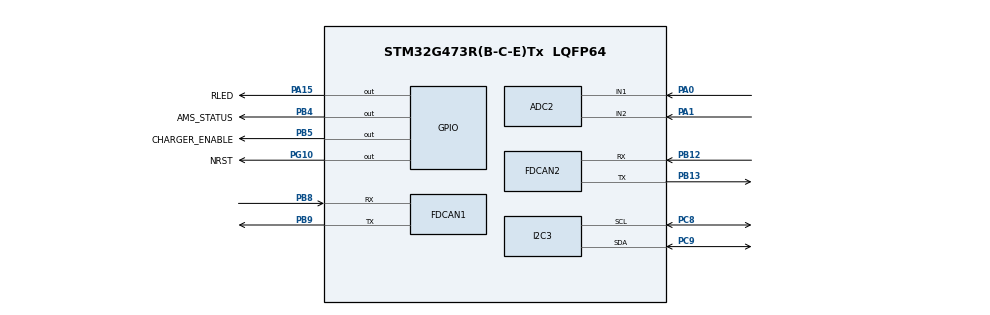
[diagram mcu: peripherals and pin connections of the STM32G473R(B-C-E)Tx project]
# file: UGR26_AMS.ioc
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ADC2.Channel-1\#ChannelRegularConversion=ADC_CHANNEL_1
ADC2.NbrOfConversionFlag=1
ADC2.OffsetNumber-1\#ChannelRegularConversion=ADC_OFFSET_NONE
ADC2.Rank-1\#ChannelRegularConversion=1
ADC2.SamplingTime-1\#ChannelRegularConversion=ADC_SAMPLETIME_2CYCLES_5
ADC2.SingleDiff-1\#ChannelRegularConversion=ADC_DIFFERENTIAL_ENDED
FDCAN1.CalculateBaudRateNominal=333333
FDCAN1.CalculateTimeBitNominal=3000
FDCAN1.CalculateTimeQuantumNominal=1000.0
FDCAN1.DataPrescaler=6
FDCAN1.DataTimeSeg1=13
FDCAN1.DataTimeSeg2=2
FDCAN2.CalculateBaudRateNominal=333333
FDCAN2.CalculateTimeBitNominal=3000
FDCAN2.CalculateTimeQuantumNominal=1000.0
FDCAN2.DataPrescaler=6
FDCAN2.DataTimeSeg1=13
FDCAN2.DataTimeSeg2=2
I2C3.Timing=0x00503D58
Mcu.Family=STM32G4
Mcu.Name=STM32G473R(B-C-E)Tx
Mcu.Package=LQFP64
NVIC.PriorityGroup=NVIC_PRIORITYGROUP_4
PA0.Mode=IN1-Differential
PA0.Signal=ADC2_IN1
PA1.Mode=IN1-Differential
PA1.Signal=ADC2_IN2
PA13.Mode=Serial_Wire
PA13.Signal=SYS_JTMS-SWDIO
PA14.Mode=Serial_Wire
PA14.Signal=SYS_JTCK-SWCLK
PA15.GPIO_Label=RLED
PA15.Signal=GPIO_Output
PB12.Mode=FDCAN_Activate
PB12.Signal=FDCAN2_RX
PB13.Mode=FDCAN_Activate
PB13.Signal=FDCAN2_TX
PB4.GPIO_Label=AMS_STATUS
PB4.Signal=GPIO_Output
PB5.GPIO_Label=CHARGER_ENABLE
PB5.Signal=GPIO_Output
PB8-BOOT0.Mode=FDCAN_Activate
PB8-BOOT0.Signal=FDCAN1_RX
PB9.Mode=FDCAN_Activate
PB9.Signal=FDCAN1_TX
PC8.Mode=I2C
PC8.Signal=I2C3_SCL
PC9.Mode=I2C
PC9.Signal=I2C3_SDA
PG10-NRST.GPIO_Label=NRST
PG10-NRST.Signal=GPIO_Output
ProjectManager.HeapSize=0x200
ProjectManager.StackSize=0x400
ProjectManager.TargetToolchain=STM32CubeIDE
RCC.ADC12Freq_Value=16000000
RCC.ADC345Freq_Value=16000000
RCC.AHBFreq_Value=16000000
RCC.APB1Freq_Value=16000000
RCC.APB1TimFreq_Value=16000000
RCC.APB2Freq_Value=16000000
RCC.APB2TimFreq_Value=16000000
RCC.CortexFreq_Value=16000000
RCC.EXTERNAL_CLOCK_VALUE=12288000
RCC.HCLKFreq_Value=16000000
RCC.HSE_VALUE=48000000
RCC.HSI48_VALUE=48000000
RCC.HSI_VALUE=16000000
RCC.LSE_VALUE=32768
RCC.SYSCLKFreq_VALUE=16000000
RCC.USBFreq_Value=64000000
RCC.VCOOutputFreq_Value=128000000
VP_LPTIM1_VS_LPTIM_counterModeInternalClock.Mode=Counts__internal_clock_event_00
VP_SYS_VS_DBSignals.Mode=DisableDeadBatterySignals
VP_WWDG_VS_WWDG.Mode=WWDG_Activate
board=custom

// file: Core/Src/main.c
/* USER CODE BEGIN Header */
/**
  ******************************************************************************
  * @file           : main.c
  * @brief          : Main program body
  ******************************************************************************
  * @attention
  *
  * Copyright (c) 2025 STMicroelectronics.
  * All rights reserved.
  *
  * This software is licensed under terms that can be found in the LICENSE file
  * in the root directory of this software component.
  * If no LICENSE file comes with this software, it is provided AS-IS.
  *
  ******************************************************************************
  */
/* USER CODE END Header */
#include "main.h"
#include "adc.h"
#include "fdcan.h"
#include "i2c.h"
#include "lptim.h"
#include "wwdg.h"
#include "gpio.h"
#include "system_monitor.h"
#include "diagnostics.h"
#include "scheduler.h"

void SystemClock_Config(void);

/* USER CODE BEGIN 0 */

// Wrapper function for scheduler - ADC task returns a value but scheduler expects void
static void ADC_SchedulerTask(void) {
    (void)ADC2_GetTSCurrent();  // Call ADC and discard return value
}

static void WWDG_SchedulerTask(void) {
  (void)WWDG_Refresh();
}

/* USER CODE END 0 */

int main(void){

  /* MCU Configuration--------------------------------------------------------*/

  /* Reset of all peripherals, Initializes the Flash interface and the Systick. */
  HAL_Init();

  /* Configure the system clock */
  SystemClock_Config();

  /* Initialize all configured peripherals */
  MX_GPIO_Init();
  MX_ADC2_Init();
  MX_FDCAN1_Init();
  MX_FDCAN2_Init();
  MX_I2C3_Init();
  MX_LPTIM1_Init();
  MX_WWDG_Init();

  SystemMonitor_Init();
  Diagnostics_Init();

  /* Initialize and configure FDCAN1 */
  MX_FDCAN1_Init();
  FDCAN1_Config_And_Start();

  /* Initialize and configure FDCAN2 (if using both) */
  MX_FDCAN2_Init();
  FDCAN2_Config_And_Start();

  CheckChargerConnection(); // set mode for AMS - should not change during one power cycle

  Scheduler_Init();

  Scheduler_AddTask(ADC_SchedulerTask, 20);             // 20ms
  Scheduler_AddTask(WWDG_SchedulerTask, 50);            // 50ms
  Scheduler_AddTask(SystemMonitor_Update, 100);         // 100ms
  Scheduler_AddTask(UpdateAMSStatus, 100);              // 100ms
  Scheduler_AddTask(Diagnostics_PerformCheck, 1000);    // 1000ms

  while (1){
    Scheduler_RunTasks();
  }
}

void SystemClock_Config(void)
{
  RCC_OscInitTypeDef RCC_OscInitStruct = {0};
  RCC_ClkInitTypeDef RCC_ClkInitStruct = {0};

  /** Configure the main internal regulator output voltage
  */
  HAL_PWREx_ControlVoltageScaling(PWR_REGULATOR_VOLTAGE_SCALE1);

  /** Initializes the RCC Oscillators according to the specified parameters
  * in the RCC_OscInitTypeDef structure.
  */
  RCC_OscInitStruct.OscillatorType = RCC_OSCILLATORTYPE_HSE;
  RCC_OscInitStruct.HSEState = RCC_HSE_BYPASS;
  RCC_OscInitStruct.PLL.PLLState = RCC_PLL_NONE;
  if (HAL_RCC_OscConfig(&RCC_OscInitStruct) != HAL_OK)
  {
    Error_Handler();
  }

  /** Initializes the CPU, AHB and APB buses clocks
  */
  RCC_ClkInitStruct.ClockType = RCC_CLOCKTYPE_HCLK|RCC_CLOCKTYPE_SYSCLK
                              |RCC_CLOCKTYPE_PCLK1|RCC_CLOCKTYPE_PCLK2;
  RCC_ClkInitStruct.SYSCLKSource = RCC_SYSCLKSOURCE_HSE;
  RCC_ClkInitStruct.AHBCLKDivider = RCC_SYSCLK_DIV1;
  RCC_ClkInitStruct.APB1CLKDivider = RCC_HCLK_DIV1;
  RCC_ClkInitStruct.APB2CLKDivider = RCC_HCLK_DIV1;

  if (HAL_RCC_ClockConfig(&RCC_ClkInitStruct, FLASH_LATENCY_1) != HAL_OK)
  {
    Error_Handler();
  }
}

void Error_Handler(void)
{
  __disable_irq();
  while (1)
  {
  }
}
